# EZR32HG320F64R61 register map
File version: 5.8.2
CPU: CM0PLUS r0p1, little endian, no MPU, no FPU, 3 interrupt priority bits
Registers are 32-bit, read-write, reset 0x0 unless marked. A register's access mark holds for its fields unless they carry their own. Offsets are from the block's base; [hi:lo] are bit positions; {n}, {i} and the like mark numbered series.

## PCNT0
Base 0x40086000
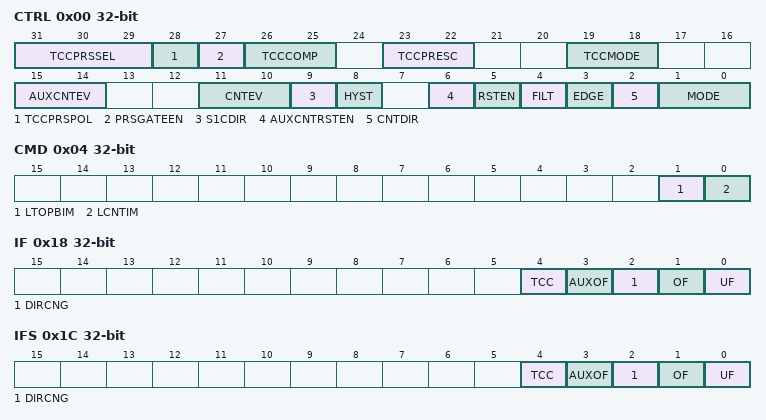
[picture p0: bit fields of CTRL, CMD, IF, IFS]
0x00 CTRL — Control Register
  [31:29] TCCPRSSEL — TCC PRS Channel Select
    {v}=PRSCH{v} (PRS Channel {v} selected.) (v=0..5)
  [28] TCCPRSPOL — TCC PRS polarity select
  [27] PRSGATEEN — PRS gate enable
  [26:25] TCCCOMP — Triggered compare and clear compare mode
    0=LTOE (Compare match if PCNT_CNT is less than, or equal to PCNT_TOP.); 1=GTOE (Compare match if PCNT_CNT is greater than or equal to PCNT_TOP.); 2=RANGE (Compare match if PCNT_CNT is less than, or equal to PCNT_TOP[15:8]], and greater than, or equal to PCNT_TOP[7:0].)
  [23:22] TCCPRESC — Set the LFA prescaler for triggered compare and clear
    0=DIV1 (Compare and clear event each LFA cycle.); 1=DIV2 (Compare and clear performed on every other LFA cycle.); 2=DIV4 (Compare and clear performed on every 4th LFA cycle.); 3=DIV8 (Compare and clear performed on every 8th LFA cycle.)
  [19:18] TCCMODE — Sets the mode for triggered compare and clear
    0=DISABLED (Triggered compare and clear not enabled.); 1=LFA (Compare and clear performed on each (optionally prescaled) LFA clock cycle.); 2=PRS (Compare and clear performed on positive PRS edges.)
  [15:14] AUXCNTEV — Controls when the auxiliary counter counts
    0=NONE (Never counts.); 1=UP (Counts up on up-count events.); 2=DOWN (Counts up on down-count events.); 3=BOTH (Counts up on both up-count and down-count events.)
  [11:10] CNTEV — Controls when the counter counts
    0=BOTH (Counts up on up-count and down on down-count events.); 1=UP (Only counts up on up-count events.); 2=DOWN (Only counts down on down-count events.); 3=NONE (Never counts.)
  [9] S1CDIR — Count direction determined by S1
  [8] HYST — Enable Hysteresis
  [6] AUXCNTRSTEN — Enable AUXCNT Reset
  [5] RSTEN — Enable PCNT Clock Domain Reset
  [4] FILT — Enable Digital Pulse Width Filter
  [3] EDGE — Edge Select
  [2] CNTDIR — Non-Quadrature Mode Counter Direction Control
  [1:0] MODE — Mode Select
    0=DISABLE (The module is disabled.); 1=OVSSINGLE (Single input LFACLK oversampling mode (available in EM0-EM2).); 2=EXTCLKSINGLE (Externally clocked single input counter mode (available in EM0-EM3).); 3=EXTCLKQUAD (Externally clocked quadrature decoder mode (available in EM0-EM3).)
0x04 CMD wo — Command Register
  [1] LTOPBIM — Load TOPB Immediately
  [0] LCNTIM — Load CNT Immediately
0x08 STATUS ro
  [0] DIR — Current Counter Direction
0x0C CNT ro — Counter Value Register
  [15:0] CNT — Counter Value
0x10 TOP ro reset 0xFF — Top Value Register
  [15:0] TOP — Counter Top Value
0x14 TOPB reset 0xFF — Top Value Buffer Register
  [15:0] TOPB — Counter Top Buffer
0x18 IF ro — Interrupt Flag Register
  [4] TCC — Triggered compare Interrupt Read Flag
  [3] AUXOF — Overflow Interrupt Read Flag
  [2] DIRCNG — Direction Change Detect Interrupt Flag
  [1] OF — Overflow Interrupt Read Flag
  [0] UF — Underflow Interrupt Read Flag
0x1C IFS wo — Interrupt Flag Set Register
  [4] TCC — Triggered compare Interrupt Set
  [3] AUXOF — Auxiliary Overflow Interrupt Set
  [2] DIRCNG — Direction Change Detect Interrupt Set
  [1] OF — Overflow Interrupt Set
  [0] UF — Underflow interrupt set
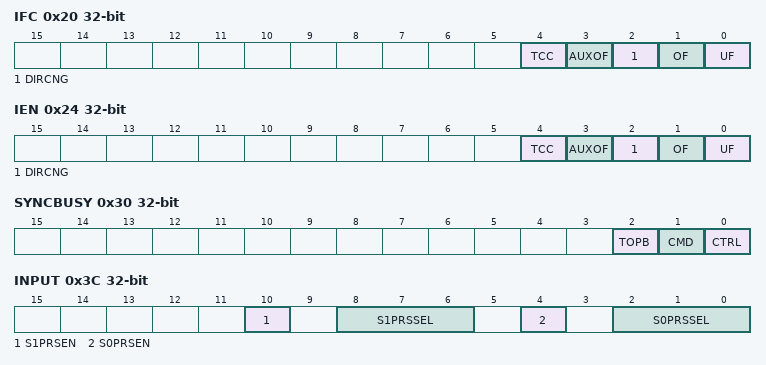
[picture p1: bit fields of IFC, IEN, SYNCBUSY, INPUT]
0x20 IFC wo — Interrupt Flag Clear Register
  [4] TCC — Triggered compare Interrupt Clear
  [3] AUXOF — Auxiliary Overflow Interrupt Clear
  [2] DIRCNG — Direction Change Detect Interrupt Clear
  [1] OF — Overflow Interrupt Clear
  [0] UF — Underflow Interrupt Clear
0x24 IEN — Interrupt Enable Register
  [4] TCC — Triggered compare Interrupt Enable
  [3] AUXOF — Auxiliary Overflow Interrupt Enable
  [2] DIRCNG — Direction Change Detect Interrupt Enable
  [1] OF — Overflow Interrupt Enable
  [0] UF — Underflow Interrupt Enable
0x28 ROUTE — I/O Routing Register
  [10:8] LOCATION — I/O Location
    {v}=LOC{v} (Location {v}) (v=0..4)
0x2C FREEZE
  [0] REGFREEZE — Register Update Freeze
0x30 SYNCBUSY ro — Synchronization Busy Register
  [2] TOPB — TOPB Register Busy
  [1] CMD — CMD Register Busy
  [0] CTRL — CTRL Register Busy
0x38 AUXCNT — Auxiliary Counter Value Register
  [15:0] AUXCNT — Auxiliary Counter Value
0x3C INPUT — PCNT Input Register
  [10] S1PRSEN — S1IN PRS Enable
  [8:6] S1PRSSEL — S1IN PRS Channel Select
    {v}=PRSCH{v} (PRS Channel {v} selected.) (v=0..5)
  [4] S0PRSEN — S0IN PRS Enable
  [2:0] S0PRSSEL — S0IN PRS Channel Select
    {v}=PRSCH{v} (PRS Channel {v} selected.) (v=0..5)

## Notices in the file
# License
Copyright 2019 Silicon Laboratories Inc. www.silabs.com
SPDX-License-Identifier: Zlib
The licensor of this software is Silicon Laboratories Inc.
This software is provided 'as-is', without any express or implied
warranty. In no event will the authors be held liable for any damages
arising from the use of this software.
Permission is granted to anyone to use this software for any purpose,
including commercial applications, and to alter it and redistribute it
freely, subject to the following restrictions:
1. The origin of this software must not be misrepresented; you must not
claim that you wrote the original software. If you use this software
in a product, an acknowledgment in the product documentation would be
appreciated but is not required.
2. Altered source versions must be plainly marked as such, and must not be
misrepresented as being the original software.
3. This notice may not be removed or altered from any source distribution.
